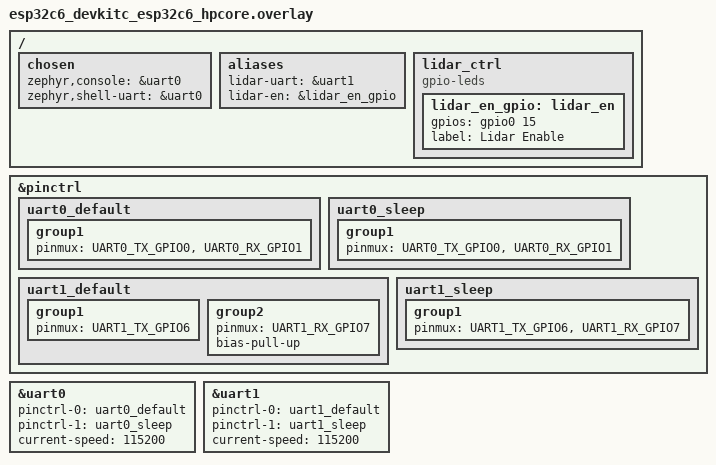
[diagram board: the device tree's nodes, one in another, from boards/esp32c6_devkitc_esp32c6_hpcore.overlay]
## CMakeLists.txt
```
cmake_minimum_required(VERSION 3.20.0)

find_package(Zephyr REQUIRED HINTS $ENV{ZEPHYR_BASE})
project(lidar_debug)

target_sources(app PRIVATE src/main.cpp)
```

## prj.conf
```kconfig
# General config
CONFIG_PICOLIBC=y
CONFIG_CPP=y
CONFIG_STD_CPP20=y

# Bootloader
CONFIG_ESP_SIMPLE_BOOT=y

# Logging
CONFIG_LOG=y
CONFIG_LOG_MODE_IMMEDIATE=y
CONFIG_LOG_DEFAULT_LEVEL=3

# Console
CONFIG_CONSOLE=y
CONFIG_UART_CONSOLE=y
CONFIG_SERIAL=y
CONFIG_GPIO=y
```

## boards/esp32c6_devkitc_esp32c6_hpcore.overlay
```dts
#include <zephyr/dt-bindings/pinctrl/esp-pinctrl-common.h>
#include <zephyr/dt-bindings/pinctrl/esp32c6-pinctrl.h>

/ {
    chosen {
        zephyr,console = &uart0;
        zephyr,shell-uart = &uart0;
    };

    aliases {
        lidar-uart = &uart1;
        lidar-en = &lidar_en_gpio;
    };

    lidar_ctrl {
        compatible = "gpio-leds";
        lidar_en_gpio: lidar_en {
            gpios = <&gpio0 15 GPIO_ACTIVE_HIGH>;
            label = "Lidar Enable";
        };
    };
};

&pinctrl {
    uart0_default: uart0_default {
        group1 {
            pinmux = <UART0_TX_GPIO0>,
                     <UART0_RX_GPIO1>;
        };
    };

    uart0_sleep: uart0_sleep {
        group1 {
            pinmux = <UART0_TX_GPIO0>,
                     <UART0_RX_GPIO1>;
        };
    };

    uart1_default: uart1_default {
        group1 {
            pinmux = <UART1_TX_GPIO6>;
        };
        group2 {
            pinmux = <UART1_RX_GPIO7>;
            bias-pull-up;
        };
    };

    uart1_sleep: uart1_sleep {
        group1 {
            pinmux = <UART1_TX_GPIO6>,
                     <UART1_RX_GPIO7>;
        };
    };
};

&uart0 {
    status = "okay";
    pinctrl-0 = <&uart0_default>;
    pinctrl-1 = <&uart0_sleep>;
    pinctrl-names = "default", "sleep";
    current-speed = <115200>;
};

&uart1 {
    status = "okay";
    pinctrl-0 = <&uart1_default>;
    pinctrl-1 = <&uart1_sleep>;
    pinctrl-names = "default", "sleep";
    current-speed = <115200>;
};
```

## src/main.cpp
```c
#include <zephyr/kernel.h>
#include <zephyr/device.h>
#include <zephyr/drivers/uart.h>
#include <zephyr/drivers/gpio.h>
#include <zephyr/sys/printk.h>

#define LIDAR_UART DT_ALIAS(lidar_uart)
#define LIDAR_EN   DT_ALIAS(lidar_en)

static const struct device *uart_dev = DEVICE_DT_GET(LIDAR_UART);
static const struct gpio_dt_spec motor_gpio = GPIO_DT_SPEC_GET(LIDAR_EN, gpios);

int main(void) {
    printk("\n--- RPLIDAR Minimal Debug App ---\n");

    if (!device_is_ready(uart_dev)) {
        printk("Error: UART device not ready\n");
        return 1;
    }

    if (!gpio_is_ready_dt(&motor_gpio)) {
        printk("Error: Motor GPIO not ready\n");
        return 1;
    }

    gpio_pin_configure_dt(&motor_gpio, GPIO_OUTPUT_ACTIVE);
    printk("LiDAR Motor ENABLED\n");

    // Give it time to spin up
    k_msleep(1000);

    // RESET Command
    /*
    printk("Sending RESET (0xA5 0x40)...\n");
    uart_poll_out(uart_dev, 0xA5);
    uart_poll_out(uart_dev, 0x40);

    // Wait for reset banner
    k_msleep(2000);
    */

    // Flush any power-up/reset noise
    uint8_t dummy;
    int flushed = 0;
    while (uart_poll_in(uart_dev, &dummy) == 0) {
        flushed++;
    }
    printk("Flushed %d bytes of initial noise\n", flushed);

    // SCAN Command
    printk("Sending SCAN (0xA5 0x20)...\n");
    uart_poll_out(uart_dev, 0xA5);
    uart_poll_out(uart_dev, 0x20);

    printk("Entering read loop. Printing all bytes received (hex). Resending SCAN every 5s.\n");

    uint32_t total_received = 0;
    int64_t last_cmd_sent = k_uptime_get();

    while (1) {
        uint8_t rx_byte;
        if (uart_poll_in(uart_dev, &rx_byte) == 0) {
            printk("0x%02x ", rx_byte);
            total_received++;
            if (total_received % 16 == 0) {
                printk("\n");
            }
        }

        if (k_uptime_get() - last_cmd_sent > 5000) {
            printk("\n[Periodic] Resending SCAN (0xA5 0x20)...\n");
            uart_poll_out(uart_dev, 0xA5);
            uart_poll_out(uart_dev, 0x20);
            last_cmd_sent = k_uptime_get();
        }

        k_yield();
    }
}
```
